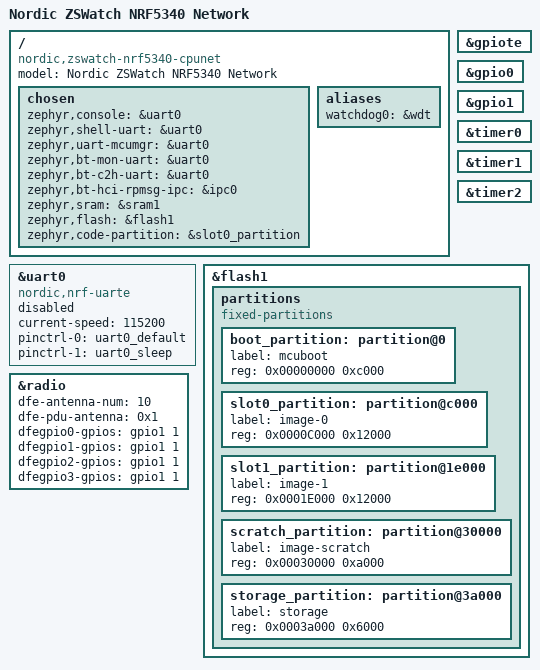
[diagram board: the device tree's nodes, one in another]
/*
 * Copyright (c) 2023 Jakob Krantz
 *
 * SPDX-License-Identifier: Apache-2.0
 */

/dts-v1/;
#include <nordic/nrf5340_cpunet_qkaa.dtsi>
#include "zswatch_nrf5340_cpunet-pinctrl.dtsi"

/ {
	model = "Nordic ZSWatch NRF5340 Network";
	compatible = "nordic,zswatch-nrf5340-cpunet";

	chosen {
		zephyr,console = &uart0;
		zephyr,shell-uart = &uart0;
		zephyr,uart-mcumgr = &uart0;
		zephyr,bt-mon-uart = &uart0;
		zephyr,bt-c2h-uart = &uart0;
		zephyr,bt-hci-rpmsg-ipc = &ipc0;
		zephyr,sram = &sram1;
		zephyr,flash = &flash1;
		zephyr,code-partition = &slot0_partition;
	};

	aliases {
		watchdog0 = &wdt;
	};
};

&gpiote {
	status = "okay";
};

&gpio0 {
	status = "okay";
};

&gpio1 {
	status = "okay";
};

&uart0 {
	compatible = "nordic,nrf-uarte";
	status = "disabled";
	current-speed = <115200>;
	pinctrl-0 = <&uart0_default>;
	pinctrl-1 = <&uart0_sleep>;
	pinctrl-names = "default", "sleep";
};

&timer0 {
	status = "okay";
};

&timer1 {
	status = "okay";
};

&timer2 {
	status = "okay";
};

&flash1 {

	partitions {
		compatible = "fixed-partitions";
		#address-cells = <1>;
		#size-cells = <1>;

		boot_partition: partition@0 {
			label = "mcuboot";
			reg = <0x00000000 0xc000>;
		};
		slot0_partition: partition@c000 {
			label = "image-0";
			reg = <0x0000C000 0x12000>;
		};
		slot1_partition: partition@1e000 {
			label = "image-1";
			reg = <0x0001E000 0x12000>;
		};
		scratch_partition: partition@30000 {
			label = "image-scratch";
			reg = <0x00030000 0xa000>;
		};
		storage_partition: partition@3a000 {
			label = "storage";
			reg = <0x0003a000 0x6000>;
		};
	};
};

// Zephyr gets mad if this is not set, even thought we don't do any switching
&radio {
	status = "okay";
	dfe-antenna-num = <10>;
	dfe-pdu-antenna = <0x1>;
	dfegpio0-gpios = <&gpio1 1 0>;
	dfegpio1-gpios = <&gpio1 1 0>;
	dfegpio2-gpios = <&gpio1 1 0>;
	dfegpio3-gpios = <&gpio1 1 0>;
};

/* Include shared RAM configuration file */
#include "zswatch_nrf5340_shared_sram_planning_conf.dts"
